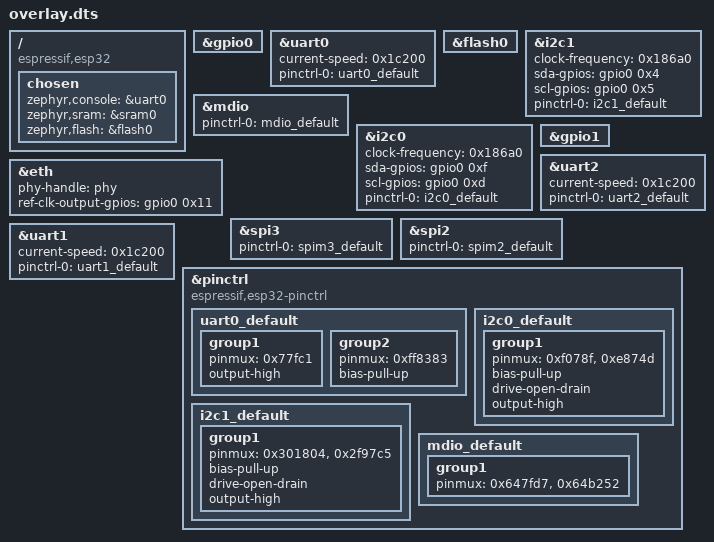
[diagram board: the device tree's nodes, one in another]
/ {
	compatible = "espressif,esp32";
	chosen {
		zephyr,console = &uart0;
		zephyr,sram = &sram0;
		zephyr,flash = &flash0;
	};
};
&gpio0{
	status = "okay";
};
&uart0{
	status = "okay";
	current-speed = < 0x1c200 >;
	pinctrl-0 = < &uart0_default >;
	pinctrl-names = "default";
};
&flash0{
	status = "okay";
};
&i2c1{
	status = "okay";
	clock-frequency = < 0x186a0 >;
	sda-gpios = < &gpio0 0x4 0x6 >;
	scl-gpios = < &gpio0 0x5 0x6 >;
	pinctrl-0 = < &i2c1_default >;
	pinctrl-names = "default";
};
&mdio{
	status = "okay";
	pinctrl-0 = < &mdio_default >;
	pinctrl-names = "default";
};
&i2c0{
	status = "okay";
	clock-frequency = < 0x186a0 >;
	sda-gpios = < &gpio0 0xf 0x6 >;
	scl-gpios = < &gpio0 0xd 0x6 >;
	pinctrl-0 = < &i2c0_default >;
	pinctrl-names = "default";
};
&gpio1{
	status = "okay";
};
&eth{
	status = "okay";
	phy-handle = < &phy >;
	ref-clk-output-gpios = < &gpio0 0x11 0x0 >;
};
&uart2{
	current-speed = < 0x1c200 >;
	pinctrl-0 = < &uart2_default >;
	pinctrl-names = "default";
};
&spi3{
	status = "okay";
	#address-cells = < 0x1 >;
	#size-cells = < 0x0 >;
	pinctrl-0 = < &spim3_default >;
	pinctrl-names = "default";
};
&spi2{
	status = "okay";
	#address-cells = < 0x1 >;
	#size-cells = < 0x0 >;
	pinctrl-0 = < &spim2_default >;
	pinctrl-names = "default";
};
&uart1{
	current-speed = < 0x1c200 >;
	pinctrl-0 = < &uart1_default >;
	pinctrl-names = "default";
};
&pinctrl{
	compatible = "espressif,esp32-pinctrl";
	status = "okay";
	uart0_default: uart0_default {
		group1 {
			pinmux = < 0x77fc1 >;
			output-high;
		};
		group2 {
			pinmux = < 0xff8383 >;
			bias-pull-up;
		};
	};
	i2c0_default: i2c0_default {
		group1 {
			pinmux = < 0xf078f >, < 0xe874d >;
			bias-pull-up;
			drive-open-drain;
			output-high;
		};
	};
	i2c1_default: i2c1_default {
		group1 {
			pinmux = < 0x301804 >, < 0x2f97c5 >;
			bias-pull-up;
			drive-open-drain;
			output-high;
		};
	};
	mdio_default: mdio_default {
		group1 {
			pinmux = < 0x647fd7 >, < 0x64b252 >;
		};
	};
};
